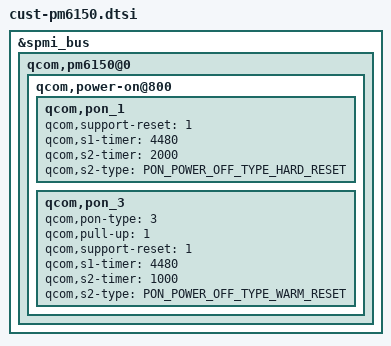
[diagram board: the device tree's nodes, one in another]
#include <dt-bindings/input/qcom,qpnp-power-on.h>

&spmi_bus {
	qcom,pm6150@0 {
		qcom,power-on@800 {
			qcom,pon_1 {
				qcom,support-reset = <1>;
				qcom,s1-timer = <4480>;
				qcom,s2-timer = <2000>;
				qcom,s2-type = <PON_POWER_OFF_TYPE_HARD_RESET>;
			};

			qcom,pon_3 {
				qcom,pon-type = <3>;
				qcom,pull-up = <1>;
				qcom,support-reset = <1>;
				qcom,s1-timer = <4480>;
				qcom,s2-timer = <1000>;
				qcom,s2-type = <PON_POWER_OFF_TYPE_WARM_RESET>;
			};
		};
	};
};
